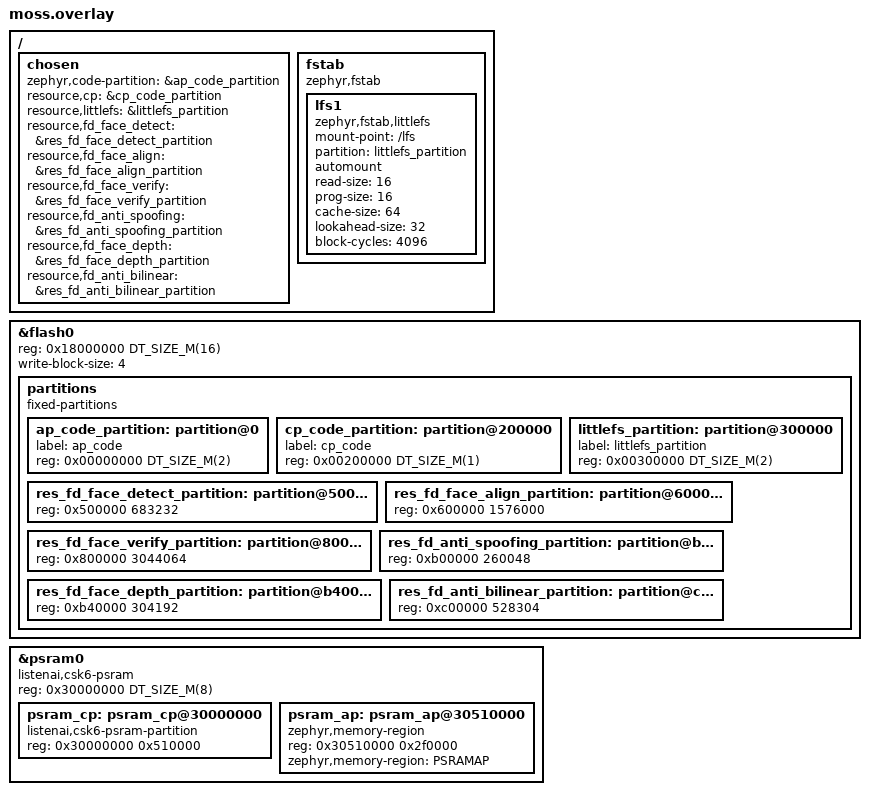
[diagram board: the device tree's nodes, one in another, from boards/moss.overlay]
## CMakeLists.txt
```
# SPDX-License-Identifier: Apache-2.0

cmake_minimum_required(VERSION 3.20.0)

set(SDK_ROOT_PATH  $ENV{ZEPHYR_BASE}/../duomotai_ap)

list(APPEND ZEPHYR_EXTRA_MODULES ${SDK_ROOT_PATH}/components)

find_package(Zephyr REQUIRED HINTS $ENV{ZEPHYR_BASE})

project(moss)

target_sources(app PRIVATE
  src/main.c
  src/comp_fd.c
  src/indicator.c
)

target_sources_ifdef(CONFIG_DISPLAY_DEBUG app PRIVATE
  src/display.c
  src/screen.c
)

target_link_libraries(app PRIVATE lsf_client)

add_subdirectory(resources)
```

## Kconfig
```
# Copyright (c) 2023 Anhui Listenai Co., Ltd.
# SPDX-License-Identifier: Apache-2.0

rsource "resources/Kconfig"

config WEBUSB_DEBUG
	default n
	select GCL_WEBUSB
	select WEBUSB

config DISPLAY_DEBUG
	bool "Enable display debug"
	default y
	select DISPLAY
	select ST7789V_MOSS
	select LVGL

if DISPLAY_DEBUG
config DISPLAY_DEBUG_SHOW_FPS
	bool "Show FPS"
	default n
endif # DISPLAY_DEBUG

config FD_ANTI_SPOOFING
	bool "Enable anti-spoofing"
	default n

module = APP
module-str = app
source "subsys/logging/Kconfig.template.log_config"

rsource "Kconfig.capability"

source "Kconfig.zephyr"
```

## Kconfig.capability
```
# Copyright (c) 2023 Anhui Listenai Co., Ltd.
# SPDX-License-Identifier: Apache-2.0

config CAPABILITY_FD
	bool "Enable FD"
	select GCP
	select GCL_COMP_RES
	select GCS_SERVICE_FD
	select GCL_FD
	default n

if CAPABILITY_FD
	config GCL_HEAP_SRAM_SIZE
		default 40960

	config GCL_HEAP_PSRAM_SIZE
		default 81920

	config GCL_HEAP_SRAM_NOCACHE_SIZE
		default 20480

	config GCL_HEAP_PSRAM_NOCACHE_SIZE
		default 20480
endif
```

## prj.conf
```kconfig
# Copyright (c) 2023 Anhui Listenai Co., Ltd.
# SPDX-License-Identifier: Apache-2.0

CONFIG_LOG=y

CONFIG_NEWLIB_LIBC=y
CONFIG_NEWLIB_LIBC_FLOAT_PRINTF=y
CONFIG_NEWLIB_LIBC_FLOAT_SCANF=y

CONFIG_MAIN_STACK_SIZE=4096
CONFIG_SYSTEM_WORKQUEUE_STACK_SIZE=4096
CONFIG_HEAP_MEM_POOL_SIZE=81920
CONFIG_CSK_HEAP=y
CONFIG_CSK_HEAP_MEM_POOL_SIZE=307200

CONFIG_GPIO=y

CONFIG_VIDEO=y
CONFIG_VIDEO_CSK6_DVP=y
CONFIG_VIDEO_GC0328=y
CONFIG_VIDEO_BUFFER_POOL_SZ_MAX=614800
CONFIG_VIDEO_BUFFER_POOL_NUM_MAX=3
CONFIG_VIDEO_CUSTOM_SECTION=y
CONFIG_VIDEO_CUSTOM_SECTION_NAME=".psram_section"

CONFIG_SPI=y
CONFIG_I2C=y

CONFIG_ST7789V=n

CONFIG_INPUT=y
CONFIG_INPUT_FT5336=n

CONFIG_ADC=n
CONFIG_ADC_CSK6_CH32V003=n

CONFIG_LV_COLOR_DEPTH_16=y
CONFIG_LV_FONT_MONTSERRAT_14=y

CONFIG_LV_Z_DRIVER_CSK6_16BIT=y
CONFIG_LV_Z_DRIVER_CSK6_16BIT_ROTATE_90=n
CONFIG_LV_Z_DRIVER_CSK6_16BIT_THREAD_PRIORITY=1
CONFIG_LV_Z_DRIVER_CSK6_KSAN_FILTER_TIME_MS=50

CONFIG_LV_MEM_CUSTOM=y
CONFIG_LV_Z_MEM_CUSTOM_SECTION=y
CONFIG_LV_Z_MEM_CUSTOM_SECTION_NAME=".psram_section"
CONFIG_LV_Z_MEM_POOL_MAX_SIZE=1024
CONFIG_LV_Z_MEM_POOL_NUMBER_BLOCKS=500

CONFIG_LV_Z_DOUBLE_VDB=y
CONFIG_LV_Z_VDB_SIZE=100
CONFIG_LV_Z_BUFFER_ALLOC_DYNAMIC=y

CONFIG_DISK_MEMORY=n

CONFIG_LSF=y
CONFIG_LSF_CLIENT=y
CONFIG_LSF_OS_ZEPHYR=y
CONFIG_LSF_IC_MESSAGE_EP_ID=5

CONFIG_CAPABILITY_FD=y
```

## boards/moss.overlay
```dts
/ {
	chosen {
		zephyr,code-partition = &ap_code_partition;
		resource,cp = &cp_code_partition;
		resource,littlefs = &littlefs_partition;
		resource,fd_face_detect = &res_fd_face_detect_partition;
		resource,fd_face_align = &res_fd_face_align_partition;
		resource,fd_face_verify = &res_fd_face_verify_partition;
		resource,fd_anti_spoofing = &res_fd_anti_spoofing_partition;
		resource,fd_face_depth = &res_fd_face_depth_partition;
		resource,fd_anti_bilinear = &res_fd_anti_bilinear_partition;
	};

	fstab {
		compatible = "zephyr,fstab";
		lfs1: lfs1 {
			compatible = "zephyr,fstab,littlefs";
			mount-point = "/lfs";
			partition = <&littlefs_partition>;
			automount;
			read-size = <16>;
			prog-size = <16>;
			cache-size = <64>;
			lookahead-size = <32>;
			block-cycles = <4096>;
		};
	};
};

&flash0 {
	reg = <0x18000000 DT_SIZE_M(16)>;
	write-block-size = <4>;
	partitions {
		compatible = "fixed-partitions";
		#address-cells = <1>;
		#size-cells = <1>;

		ap_code_partition: partition@0 {
			label = "ap_code";
			reg = <0x00000000 DT_SIZE_M(2)>;
		};

		cp_code_partition: partition@200000 {
			label = "cp_code";
			reg = <0x00200000 DT_SIZE_M(1)>;
		};

		littlefs_partition: partition@300000 {
			label = "littlefs_partition";
			reg = <0x00300000 DT_SIZE_M(2)>;
		};

		res_fd_face_detect_partition: partition@500000 {
			reg = <0x500000 683232>;
		};

		res_fd_face_align_partition: partition@600000 {
			reg = <0x600000 1576000>;
		};

		res_fd_face_verify_partition: partition@800000 {
			reg = <0x800000 3044064>;
		};

		res_fd_anti_spoofing_partition: partition@b00000 {
			reg = <0xb00000 260048>;
		};

		res_fd_face_depth_partition: partition@b40000 {
			reg = <0xb40000 304192>;
		};

		res_fd_anti_bilinear_partition: partition@c00000 {
			reg = <0xc00000 528304>;
		};
	};
};

&psram0 {
	compatible = "listenai,csk6-psram";
	reg = <0x30000000 DT_SIZE_M(8)>;
	#address-cells = <0x1>;
	#size-cells = <0x1>;

	psram_cp: psram_cp@30000000 {
		compatible = "listenai,csk6-psram-partition";
		reg = <0x30000000 0x510000>;
		status = "okay";
	};

	psram_ap: psram_ap@30510000 {
		compatible = "zephyr,memory-region",
			     "listenai,csk6-psram-partition";
		reg = <0x30510000 0x2f0000>;
		status = "okay";
		zephyr,memory-region = "PSRAMAP";
	};
};
```

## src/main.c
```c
/*
 * Copyright (c) 2023 Anhui Listenai Co., Ltd.
 * SPDX-License-Identifier: Apache-2.0
 */

#include <zephyr/kernel.h>
#include <zephyr/devicetree.h>
#include <zephyr/drivers/gpio.h>
#include <zephyr/input/input.h>
#include <zephyr/device.h>
#include <zephyr/drivers/video.h>

#include "boot_cp.h"
#include "ic_message.h"
#include "resource_load.h"
#include "comp_fd.h"
#if defined(CONFIG_DISPLAY_DEBUG)
#include "display.h"
#endif /* CONFIG_DISPLAY_DEBUG */

#define CP_FLASH_BASE_ADDRESS        (0x68000000)
#define FLASH_CP_IMAGE_REGION_OFFSET DT_REG_ADDR(DT_NODE_BY_FIXED_PARTITION_LABEL(cp_code))
#define CP_BOOT_ADDRESS              (CP_FLASH_BASE_ADDRESS + FLASH_CP_IMAGE_REGION_OFFSET)

static const struct device *video = DEVICE_DT_GET(DT_NODELABEL(dvp));

static uint16_t last_key = 0;

static void input_work_cb(struct k_work *work)
{
	ARG_UNUSED(work);

	switch (last_key) {
	case INPUT_KEY_1:
		comp_fd_capture();
		break;
	case INPUT_KEY_2:
		comp_fd_compare();
		break;
	default:
		break;
	}
}

K_WORK_DEFINE(input_work, input_work_cb);

static void input_cb(struct input_event *evt)
{
	if (evt->type == INPUT_EV_KEY && evt->value) {
		last_key = evt->code;
		k_work_submit(&input_work);
	}
}

INPUT_LISTENER_CB_DEFINE(NULL, input_cb);

extern int webusb_gcl_init(void);

int main(void)
{
	int enable_vertical_flip = 1;
	video_set_ctrl(video, VIDEO_CID_VFLIP, (void*) &enable_vertical_flip);

	boot_cp((const void *)CP_BOOT_ADDRESS);

#if defined(CONFIG_GCL_WEBUSB)
	webusb_gcl_init();
#endif /* CONFIG_GCL_WEBUSB */

	ic_message_init();

#if defined(CONFIG_GCL_COMP_RES)
	components_resource_load();
#endif /* CONFIG_GCL_COMP_RES */

#if defined(CONFIG_DISPLAY_DEBUG)
	display_init();
#endif /* CONFIG_DISPLAY_DEBUG */

	comp_fd_init();

	return 0;
}
```

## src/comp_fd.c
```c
/*
 * Copyright (c) 2023 Anhui Listenai Co., Ltd.
 * SPDX-License-Identifier: Apache-2.0
 */

#include "comp_fd.h"

#include <stdio.h>
#include <stdint.h>
#include <string.h>
#include <stdarg.h>
#include <zephyr/kernel.h>
#include <zephyr/device.h>
#include <zephyr/drivers/uart.h>
#include <zephyr/sys/crc.h>

#include "indicator.h"
#if defined(CONFIG_DISPLAY_DEBUG)
#include "screen.h"
#endif /* CONFIG_DISPLAY_DEBUG */
#include "gcs_fd_service.h"

#define FD_UART_BUFFER_SIZE 512

/* change this to any other UART peripheral if desired */
#define FD_UART_DEVICE_NODE DT_NODELABEL(uart2)

static const struct device *const fd_uart_dev = DEVICE_DT_GET(FD_UART_DEVICE_NODE);

static fd_feature_t feature_store[FEATURES_MAX_COUNT];

static void append_crc_to_string_hex(char* str, size_t max_len, uint16_t crc)
{
    size_t len = strlen(str);
    if (len + sizeof(uint16_t) < max_len) { // 确保有足够的空间
		sprintf(str + len, "%04X\n", crc); // 将CRC格式化为十六进制字符串并附加
    }
}

static void print_uart(char *buf) 
{
	int msg_len = strlen(buf);

	for (int i = 0; i < msg_len; i++) {
		uart_poll_out(fd_uart_dev, buf[i]);
	}
}

static void sendMessage(const char *format, ...) 
{
	static char buffer[FD_UART_BUFFER_SIZE];

	va_list args;
	va_start(args, format);
	vsnprintf(buffer, FD_UART_BUFFER_SIZE, format, args);
 	va_end(args);

	printk("%s\n", buffer);

	uint16_t crc = crc16_itu_t(0x0000, buffer, strlen(buffer));

	append_crc_to_string_hex(buffer, FD_UART_BUFFER_SIZE, crc);

	print_uart(buffer);
}

static void comp_fd_info_callback(const fd_info_t *info)
{
	indicator_set_has_face(info->face != NULL && info->face->head_pose_status
#if defined(CONFIG_FD_ANTI_SPOOFING)
			       && info->face->anti_spoofing_status
#endif /* CONFIG_FD_ANTI_SPOOFING */
	);

#if defined(CONFIG_DISPLAY_DEBUG)
	screen_update_info(info);
#endif /* CONFIG_DISPLAY_DEBUG */

	if (info->face != NULL) {
		sendMessage(
				"{\"type\":\"face-info\","
				"\"face\":{\"x\":%d,\"y\":%d,\"w\":%d,\"h\":%d},"
				"\"head\":{\"yaw\":%f,\"pitch\":%f,\"roll\":%f,\"pose\":%d},"
				"\"anti_spoofing\":{\"score\":%f,\"status\":%d}}\n",
				info->face->detect_rect.x, info->face->detect_rect.y,
				info->face->detect_rect.w, info->face->detect_rect.h, info->face->head_yaw,
				info->face->head_pitch, info->face->head_roll, info->face->head_pose_status,
				info->face->anti_spoofing_score, info->face->anti_spoofing_status);
	}
}

int comp_fd_init(void)
{
	/* 初始化人脸识别服务 */
	fd_service_gcs_init();

	/* 获取当前参数、修改并设置 */
	fd_service_gcs_params_t params;
	fd_service_gcs_params_get(&params);
	params.fd_face_detect_thres = 0.4f;
	params.fd_face_align_yawthres = 30.0f;
	params.fd_face_align_pitchthres = 30.0f;
	params.fd_face_align_rollthres = 30.0f;
#if defined(CONFIG_FD_ANTI_SPOOFING)
	params.fd_anti_spoofing_thres = 0.7f;
#else  /* CONFIG_FD_ANTI_SPOOFING */
	params.fd_anti_spoofing_thres = 0.0f;
#endif /* CONFIG_FD_ANTI_SPOOFING */
	fd_service_gcs_params_set(&params);

#if defined(CONFIG_WEBUSB_DEBUG)
	/* 开启 PC 调试工具 */
	fd_service_gcs_work_mode_set(FD_GCS_WORK_MODE_DEBUG, NULL);
#endif /* CONFIG_WEBUSB_DEBUG */

#if defined(CONFIG_FD_ANTI_SPOOFING)
	/* 使能灰度模式 (活体检测必须) */
	fd_service_gcs_gray_mode_set(true);
#endif /* CONFIG_FD_ANTI_SPOOFING */

	/* 注册人脸信息回调 */
	fd_service_gcs_callback(comp_fd_info_callback);

	/* 加载人脸特征库
	 * 注意：实际应用中通常是从 Flash 加载。此处仅以一个全局数组作为示例。
	 */
	// fd_service_gcs_features_load(feature_store, ARRAY_SIZE(feature_store));

	/* 启动服务 */
	fd_service_gcs_start();

	return 0;
}

int comp_fd_capture(void)
{
	int ret;
	bool succeed;
	uint32_t count;

	/* 将当前人脸特征抓取下来 */
	ret = fd_service_gcs_feature_capture();
	printk("feature capture ret=%d\n", ret);
	succeed = ret == 0;

	/*
	 * 导出特征库
	 * 注意：实际应用中通常会将特征库写入到 Flash 中。此处仅作为示例。
	 */
	ret = fd_service_gcs_features_dump(feature_store, &count);
	printk("captured feature count: %d\n", count);

	indicator_show_registered(succeed);

#if defined(CONFIG_DISPLAY_DEBUG)
	screen_update_registered(count);
#endif /* CONFIG_DISPLAY_DEBUG */

	sendMessage(
			"{"
			"\"type\":\"face-capture\","
			"\"is_succeed\":%s,",
			"\"feature_count\":%d"
			"}",
			succeed ? "true" : "false",
			count);

	return 0;
}

int comp_fd_compare(void)
{
	uint32_t index;
	float score;
	int ret;

	/* 对比特征库中的人脸，并输出最符合的 id 和分值 */
	ret = fd_service_gcs_feature_compare(&index, &score);
	if (ret) {
		printk("compare failed: %d\n", ret);
		return ret;
	}
	printk("index: %d, score: %f\n", index, score);

	/* 此处示例将分值大于 0.8 认为是同一个人，实际应用中需要根据实际情况调整 */
	bool pass = score > 0.8f;

	indicator_set_result(pass);

#if defined(CONFIG_DISPLAY_DEBUG)
	screen_update_compare(index, score, pass);
#endif /* CONFIG_DISPLAY_DEBUG */

	sendMessage(
			"{"
			"\"type\":\"face-compare\","
			"\"is_succeed\":%s,"
			"\"feature_id\":%d,"
			"\"score\":%f"
			"}",
			ret == 0 ? "true" : "false",
			index,
			score);

	return 0;
}
```

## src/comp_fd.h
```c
/*
 * Copyright (c) 2023 Anhui Listenai Co., Ltd.
 * SPDX-License-Identifier: Apache-2.0
 */

#pragma once

#ifdef CONFIG_CAPABILITY_FD
int comp_fd_init(void);
int comp_fd_capture(void);
int comp_fd_compare(void);
#else
static inline int comp_fd_init(void)
{
	return 0;
}

static inline int comp_fd_capture(void)
{
	return 0;
}

static inline int comp_fd_compare(void)
{
	return 0;
}
#endif
```

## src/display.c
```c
/*
 * Copyright (c) 2023 Anhui Listenai Co., Ltd.
 * SPDX-License-Identifier: Apache-2.0
 */

#include <zephyr/kernel.h>
#include <zephyr/device.h>
#include <zephyr/drivers/display.h>

#include <lvgl.h>

#include "screen.h"

#include <zephyr/logging/log.h>
LOG_MODULE_REGISTER(display, CONFIG_APP_LOG_LEVEL);

#define DISPLAY_THREAD_STACK_SIZE KB(8)
#define DISPLAY_THREAD_PRIORITY   7

static const struct device *display = DEVICE_DT_GET(DT_CHOSEN(zephyr_display));

K_THREAD_STACK_DEFINE(display_work_stack, DISPLAY_THREAD_STACK_SIZE);
static struct k_work_q display_work_q;

static void display_tick_cb(struct k_work *work)
{
	ARG_UNUSED(work);

	lv_task_handler();
}

K_WORK_DEFINE(display_tick_work, display_tick_cb);

static void display_timer_cb(struct k_timer *timer)
{
	ARG_UNUSED(timer);

	k_work_submit_to_queue(&display_work_q, &display_tick_work);
}

K_TIMER_DEFINE(display_timer, display_timer_cb, NULL);

int display_init(void)
{
	if (!device_is_ready(display)) {
		LOG_ERR("Display not ready: %s", display->name);
		return -ENODEV;
	}

	LOG_DBG("Display %s ready", display->name);

	lv_disp_t *disp = lv_disp_get_default();
	LOG_DBG("Display resolution: %dx%d", disp->driver->hor_res, disp->driver->ver_res);

	k_work_queue_start(&display_work_q, display_work_stack,
			   K_THREAD_STACK_SIZEOF(display_work_stack), DISPLAY_THREAD_PRIORITY,
			   NULL);

	lv_obj_t *screen = screen_create();
	lv_scr_load(screen);

	display_blanking_off(display);
	k_timer_start(&display_timer, K_MSEC(CONFIG_LV_DISP_DEF_REFR_PERIOD),
		      K_MSEC(CONFIG_LV_DISP_DEF_REFR_PERIOD));

	return 0;
}
```

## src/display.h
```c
/*
 * Copyright (c) 2023 Anhui Listenai Co., Ltd.
 * SPDX-License-Identifier: Apache-2.0
 */

#pragma once

int display_init(void);
```

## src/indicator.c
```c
/*
 * Copyright (c) 2023 Anhui Listenai Co., Ltd.
 * SPDX-License-Identifier: Apache-2.0
 */

#include "indicator.h"

#include <zephyr/init.h>
#include <zephyr/kernel.h>
#include <zephyr/device.h>
#include <zephyr/drivers/gpio.h>

static const struct gpio_dt_spec rgb_r = GPIO_DT_SPEC_GET(DT_ALIAS(led_rgb_red), gpios);
static const struct gpio_dt_spec rgb_g = GPIO_DT_SPEC_GET(DT_ALIAS(led_rgb_green), gpios);
static const struct gpio_dt_spec rgb_b = GPIO_DT_SPEC_GET(DT_ALIAS(led_rgb_blue), gpios);

#define INDICATOR_THREAD_STACK_SIZE KB(4)
#define INDICATOR_THREAD_PRIORITY   10

static void indicator_task(void *, void *, void *);
K_THREAD_DEFINE(indicator_thread_id, INDICATOR_THREAD_STACK_SIZE, indicator_task, NULL, NULL, NULL,
		INDICATOR_THREAD_PRIORITY, 0, 0);

enum indicator_op {
	INDICATOR_SET,
	INDICATOR_BLINK,
};

struct indicator_msg {
	enum indicator_op op;
	int r;
	int g;
	int b;
};

K_MSGQ_DEFINE(indicator_msgq, sizeof(struct indicator_msg), 10, 4);

static void indicator_set(int r, int g, int b)
{
	gpio_pin_set_dt(&rgb_r, r);
	gpio_pin_set_dt(&rgb_g, g);
	gpio_pin_set_dt(&rgb_b, b);
}

static void indicator_task(void *, void *, void *)
{
	struct indicator_msg msg;
	int cur_r = 0, cur_g = 0, cur_b = 0;

	while (1) {
		k_msgq_get(&indicator_msgq, &msg, K_FOREVER);

		switch (msg.op) {
		case INDICATOR_SET:
			indicator_set(msg.r, msg.g, msg.b);
			cur_r = msg.r;
			cur_g = msg.g;
			cur_b = msg.b;
			break;
		case INDICATOR_BLINK:
			for (int i = 0; i < 3; i++) {
				indicator_set(msg.r, msg.g, msg.b);
				k_msleep(100);
				indicator_set(0, 0, 0);
				k_msleep(100);
			}
			indicator_set(cur_r, cur_g, cur_b);
			break;
		default:
			break;
		}
	}
}

static bool last_has_face = false;

void indicator_set_has_face(bool has_face)
{
	if (last_has_face == has_face) {
		return;
	}

	if (has_face) {
		struct indicator_msg msg = {INDICATOR_SET, 1, 1, 0};
		k_msgq_put(&indicator_msgq, &msg, K_NO_WAIT);
	} else {
		struct indicator_msg msg = {INDICATOR_SET, 0, 0, 0};
		k_msgq_put(&indicator_msgq, &msg, K_NO_WAIT);
	}

	last_has_face = has_face;
}

void indicator_set_result(bool pass)
{
	if (pass) {
		struct indicator_msg msg = {INDICATOR_SET, 0, 1, 0};
		k_msgq_put(&indicator_msgq, &msg, K_NO_WAIT);
	} else {
		struct indicator_msg msg = {INDICATOR_SET, 1, 0, 0};
		k_msgq_put(&indicator_msgq, &msg, K_NO_WAIT);
	}
}

void indicator_show_registered(bool succeed)
{
	if (succeed) {
		struct indicator_msg msg = {INDICATOR_BLINK, 0, 0, 1};
		k_msgq_put(&indicator_msgq, &msg, K_NO_WAIT);
	} else {
		struct indicator_msg msg = {INDICATOR_BLINK, 1, 0, 0};
		k_msgq_put(&indicator_msgq, &msg, K_NO_WAIT);
	}
}

static int indicator_init(void)
{
	int ret;

	if (!gpio_is_ready_dt(&rgb_r)) {
		return -ENODEV;
	}

	if (!gpio_is_ready_dt(&rgb_g)) {
		return -ENODEV;
	}

	if (!gpio_is_ready_dt(&rgb_b)) {
		return -ENODEV;
	}

	ret = gpio_pin_configure_dt(&rgb_r, GPIO_OUTPUT_INACTIVE);
	if (ret < 0) {
		return ret;
	}

	ret = gpio_pin_configure_dt(&rgb_g, GPIO_OUTPUT_INACTIVE);
	if (ret < 0) {
		return ret;
	}

	ret = gpio_pin_configure_dt(&rgb_b, GPIO_OUTPUT_INACTIVE);
	if (ret < 0) {
		return ret;
	}

	indicator_set(0, 0, 0);

	return 0;
}

SYS_INIT(indicator_init, APPLICATION, CONFIG_APPLICATION_INIT_PRIORITY);
```

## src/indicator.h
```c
/*
 * Copyright (c) 2023 Anhui Listenai Co., Ltd.
 * SPDX-License-Identifier: Apache-2.0
 */

#pragma once

#include <stdbool.h>

void indicator_set_has_face(bool has_face);
void indicator_set_result(bool pass);
void indicator_show_registered(bool succeed);
```

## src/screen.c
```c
/*
 * Copyright (c) 2023 Anhui Listenai Co., Ltd.
 * SPDX-License-Identifier: Apache-2.0
 */

#include "screen.h"

#include <zephyr/devicetree.h>
#include <zephyr/kernel.h>

#include <zephyr/logging/log.h>
LOG_MODULE_REGISTER(screen, CONFIG_APP_LOG_LEVEL);

#define DISPLAY_NODE   DT_CHOSEN(zephyr_display)
#define DISPLAY_WIDTH  DT_PROP(DISPLAY_NODE, width)
#define DISPLAY_HEIGHT DT_PROP(DISPLAY_NODE, height)

#define IMAGE_WIDTH  320
#define IMAGE_HEIGHT 240

#define SPAN(n) (5 * n)

#define COLOR_RED    (lv_color_hex(0xFF0000))
#define COLOR_GREEN  (lv_color_hex(0x00FF00))
#define COLOR_YELLOW (lv_color_hex(0xFFCC00))
#define COLOR_WHITE  (lv_color_hex(0x999999))

static const int IMAGE_X_OFFSET = -(IMAGE_WIDTH - DISPLAY_WIDTH) / 2;
static const int IMAGE_Y_OFFSET = -(IMAGE_HEIGHT - DISPLAY_HEIGHT) / 2;

static lv_obj_t *preview;
static lv_obj_t *face_rect;
static lv_obj_t *detect_status;
static lv_obj_t *verify_status;
static lv_obj_t *register_status;

static lv_img_dsc_t preview_img;
static Z_GENERIC_DOT_SECTION(psram_section) uint16_t preview_buf[IMAGE_WIDTH * IMAGE_HEIGHT];

#if defined(CONFIG_DISPLAY_DEBUG_SHOW_FPS)
static lv_obj_t *fps;
static uint32_t frame_cnt = 0;

static void fps_tick_cb(struct k_work *work);
K_WORK_DEFINE(fps_tick_work, fps_tick_cb);

static void fps_timer_cb(struct k_timer *timer);
K_TIMER_DEFINE(fps_timer, fps_timer_cb, NULL);
#endif /* CONFIG_DISPLAY_DEBUG_SHOW_FPS */

lv_obj_t *screen_create(void)
{
	lv_obj_t *screen = lv_obj_create(NULL);
	lv_obj_set_scrollbar_mode(screen, LV_SCROLLBAR_MODE_OFF);

	preview = lv_img_create(screen);
	lv_obj_set_pos(preview, IMAGE_X_OFFSET, IMAGE_Y_OFFSET);
	lv_obj_set_size(preview, IMAGE_WIDTH, IMAGE_HEIGHT); 

// 	lv_obj_t *guide = lv_label_create(screen);
// 	lv_obj_set_style_text_color(guide, COLOR_RED, LV_PART_MAIN);
// 	lv_obj_set_size(guide, LV_SIZE_CONTENT, LV_SIZE_CONTENT);
// 	lv_obj_align(guide, LV_ALIGN_BOTTOM_MID, 0, SPAN(-1));
// 	lv_label_set_text_static(guide, "K1: REGISTER | K2: RECOGNIZE"
// #if defined(CONFIG_FD_ANTI_SPOOFING)
// 					" | K3: IR"
// #endif /* CONFIG_FD_ANTI_SPOOFING */
// 	);

	face_rect = lv_obj_create(screen);
	lv_obj_set_style_bg_opa(face_rect, LV_OPA_TRANSP, LV_PART_MAIN);
	lv_obj_set_style_border_width(face_rect, 1, LV_PART_MAIN);
	lv_obj_set_style_border_color(face_rect, COLOR_YELLOW, LV_PART_MAIN);
	lv_obj_set_style_radius(face_rect, 0, LV_PART_MAIN);
	lv_obj_add_flag(face_rect, LV_OBJ_FLAG_HIDDEN);

	detect_status = lv_label_create(screen);
	lv_obj_set_style_text_color(detect_status, COLOR_WHITE, LV_PART_MAIN);
	lv_obj_set_size(detect_status, LV_SIZE_CONTENT, LV_SIZE_CONTENT);
	lv_obj_align(detect_status, LV_ALIGN_TOP_LEFT, SPAN(1), SPAN(1));
	lv_label_set_text(detect_status, "has_face: 0, anti_sp: 0");

	verify_status = lv_label_create(screen);
	lv_obj_set_style_text_color(verify_status, COLOR_YELLOW, LV_PART_MAIN);
	lv_obj_set_size(verify_status, LV_SIZE_CONTENT, LV_SIZE_CONTENT);
	lv_obj_align(verify_status, LV_ALIGN_BOTTOM_LEFT, SPAN(1), SPAN(-4));
	lv_label_set_text(verify_status, "----");

	register_status = lv_label_create(screen);
	lv_obj_set_style_text_color(register_status, COLOR_YELLOW, LV_PART_MAIN);
	lv_obj_set_size(register_status, LV_SIZE_CONTENT, LV_SIZE_CONTENT);
	lv_obj_align(register_status, LV_ALIGN_BOTTOM_LEFT, SPAN(1), SPAN(-1));
	lv_label_set_text(register_status, "registered: 0");

#if defined(CONFIG_DISPLAY_DEBUG_SHOW_FPS)
	fps = lv_label_create(screen);
	lv_obj_set_style_text_color(fps, COLOR_WHITE, LV_PART_MAIN);
	lv_obj_set_size(fps, LV_SIZE_CONTENT, LV_SIZE_CONTENT);
	lv_obj_align(fps, LV_ALIGN_TOP_RIGHT, SPAN(-1), SPAN(1));
	lv_label_set_text(fps, "0 FPS");

	k_timer_start(&fps_timer, K_SECONDS(1), K_SECONDS(1));
#endif /* CONFIG_DISPLAY_DEBUG_SHOW_FPS */

	preview_img.header.cf = LV_IMG_CF_TRUE_COLOR;
	preview_img.header.w = IMAGE_WIDTH;
	preview_img.header.h = IMAGE_HEIGHT;
	preview_img.data = (uint8_t *)preview_buf;
	preview_img.data_size = sizeof(preview_buf);

	return screen;
}

void screen_update_info(const fd_info_t *info)
{
	if (info->frame.width != IMAGE_WIDTH * 2 || info->frame.height != IMAGE_HEIGHT * 2) {
		return;
	}

	/* VYUY to RGB565 and 50% point resize */
	const uint8_t *src = (const uint8_t *)info->frame.data;
	for (uint32_t y = 0; y < IMAGE_HEIGHT; y++) {
		const uint32_t src_y = y * 2;
		for (uint32_t x = 0; x < IMAGE_WIDTH; x++) {
			const uint32_t src_x = x * 2;
			const uint32_t src_idx = src_y * info->frame.width + src_x;

			const uint8_t v0 = src[src_idx * 2 + 0];
			const uint8_t y0 = src[src_idx * 2 + 1];
			const uint8_t u1 = src[src_idx * 2 + 2];
			/* y1 is not used */

			int r = y0 + 1.403f * (v0 - 128);
			int g = y0 - 0.344f * (u1 - 128) - 0.714f * (v0 - 128);
			int b = y0 + 1.770f * (u1 - 128);

			r = r < 0 ? 0 : r > 255 ? 255 : r;
			g = g < 0 ? 0 : g > 255 ? 255 : g;
			b = b < 0 ? 0 : b > 255 ? 255 : b;

			const uint16_t rgb565 = ((r >> 3) & BIT_MASK(5)) << 11 |
						((g >> 2) & BIT_MASK(6)) << 5 |
						((b >> 3) & BIT_MASK(5));

			preview_buf[y * IMAGE_WIDTH + x] = rgb565;
		}
	}

	lv_img_set_src(preview, &preview_img);

	lv_label_set_text_fmt(detect_status, "has_face: %d, anti_sp: %d",
			      info->face != NULL && info->face->head_pose_status ? 1 : 0,
			      info->face != NULL ? info->face->anti_spoofing_status : 0);

	if (info->face != NULL) {
		lv_obj_set_pos(face_rect, (lv_coord_t)(info->face->detect_rect.x / 2 + IMAGE_X_OFFSET),
			       (lv_coord_t)(info->face->detect_rect.y / 2 + IMAGE_Y_OFFSET));
		lv_obj_set_size(face_rect, (lv_coord_t)(info->face->detect_rect.w / 2),
				(lv_coord_t)(info->face->detect_rect.h / 2));
		lv_obj_clear_flag(face_rect, LV_OBJ_FLAG_HIDDEN);
	} else {
		lv_obj_add_flag(face_rect, LV_OBJ_FLAG_HIDDEN);
		lv_label_set_text(verify_status, "----");
		lv_obj_set_style_text_color(verify_status, COLOR_YELLOW, LV_PART_MAIN);
		lv_obj_set_style_text_color(register_status, COLOR_YELLOW, LV_PART_MAIN);
		lv_obj_set_style_border_color(face_rect, COLOR_YELLOW, LV_PART_MAIN);
	}

#if defined(CONFIG_DISPLAY_DEBUG_SHOW_FPS)
	frame_cnt++;
#endif /* CONFIG_DISPLAY_DEBUG_SHOW_FPS */
}

void screen_update_registered(uint32_t count)
{
	lv_label_set_text_fmt(register_status, "registered: %d", count);
}

void screen_update_compare(uint32_t index, float score, bool pass)
{
	lv_label_set_text_fmt(verify_status, "id: %d, score: %.2f", index, score);
	lv_obj_set_style_text_color(verify_status, pass ? COLOR_GREEN : COLOR_RED, LV_PART_MAIN);
	lv_obj_set_style_text_color(register_status, pass ? COLOR_GREEN : COLOR_RED, LV_PART_MAIN);
	lv_obj_set_style_border_color(face_rect, pass ? COLOR_GREEN : COLOR_RED, LV_PART_MAIN);
}

#if defined(CONFIG_DISPLAY_DEBUG_SHOW_FPS)
static void fps_tick_cb(struct k_work *work)
{
	ARG_UNUSED(work);

	lv_label_set_text_fmt(fps, "%d FPS", frame_cnt);
	frame_cnt = 0;
}

static void fps_timer_cb(struct k_timer *timer)
{
	ARG_UNUSED(timer);

	k_work_submit(&fps_tick_work);
}
#endif /* CONFIG_DISPLAY_DEBUG_SHOW_FPS */
```

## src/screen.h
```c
/*
 * Copyright (c) 2023 Anhui Listenai Co., Ltd.
 * SPDX-License-Identifier: Apache-2.0
 */

#pragma once

#include <lvgl.h>

#include "gcs_fd_service.h"

lv_obj_t *screen_create(void);

void screen_update_info(const fd_info_t *info);

void screen_update_registered(uint32_t count);

void screen_update_compare(uint32_t index, float score, bool pass);
```
